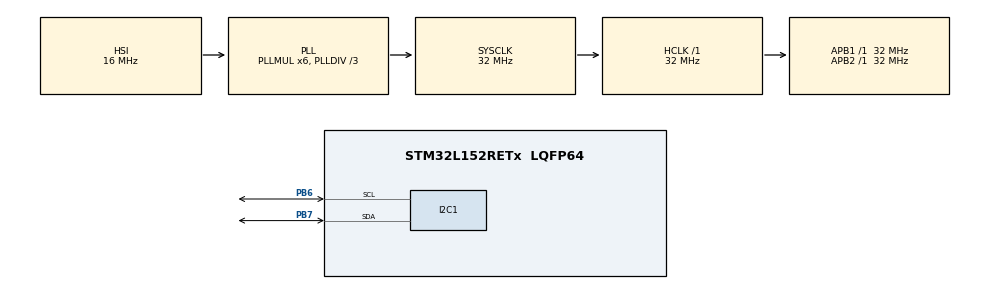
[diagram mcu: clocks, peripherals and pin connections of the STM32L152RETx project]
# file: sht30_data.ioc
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Mcu.Family=STM32L1
Mcu.Name=STM32L152RETx
Mcu.Package=LQFP64
NVIC.PriorityGroup=NVIC_PRIORITYGROUP_0
PA13.Mode=Trace_Asynchronous_SW
PA13.Signal=SYS_JTMS-SWDIO
PA14.Mode=Trace_Asynchronous_SW
PA14.Signal=SYS_JTCK-SWCLK
PB3.Mode=Trace_Asynchronous_SW
PB3.Signal=SYS_JTDO-TRACESWO
PB6.GPIO_Pu=GPIO_PULLUP
PB6.Mode=I2C
PB6.Signal=I2C1_SCL
PB7.GPIO_Pu=GPIO_PULLUP
PB7.Mode=I2C
PB7.Signal=I2C1_SDA
ProjectManager.HeapSize=0x200
ProjectManager.StackSize=0x400
ProjectManager.TargetToolchain=STM32CubeIDE
RCC.48MHZClocksFreq_Value=48000000
RCC.AHBFreq_Value=32000000
RCC.APB1Freq_Value=32000000
RCC.APB1TimFreq_Value=32000000
RCC.APB2Freq_Value=32000000
RCC.APB2TimFreq_Value=32000000
RCC.HCLKFreq_Value=32000000
RCC.HSE_VALUE=8000000
RCC.HSI_VALUE=16000000
RCC.LSE_VALUE=32768
RCC.MSI_VALUE=2097000
RCC.PLLDIV=RCC_PLL_DIV3
RCC.PLLMUL=RCC_PLL_MUL6
RCC.RTCClockSelectionVirtual=RCC_RTCCLKSOURCE_LSE
RCC.SYSCLKFreq_VALUE=32000000
RCC.SYSCLKSource=RCC_SYSCLKSOURCE_PLLCLK
RCC.USBOutput=48000000
RCC.VCOOutputFreq_Value=96000000
board=NUCLEO-L152RE

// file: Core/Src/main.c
/* USER CODE BEGIN Header */
/**
  ******************************************************************************
  * @file           : main.c
  * @brief          : Main program body
  ******************************************************************************
  * @attention
  *
  * Copyright (c) 2024 STMicroelectronics.
  * All rights reserved.
  *
  * This software is licensed under terms that can be found in the LICENSE file
  * in the root directory of this software component.
  * If no LICENSE file comes with this software, it is provided AS-IS.
  *
  ******************************************************************************
  */
/* USER CODE END Header */
#include "main.h"

/* USER CODE BEGIN Includes */
#include <string.h>
#include <stdio.h>

/* USER CODE END Includes */

I2C_HandleTypeDef hi2c1;

/* USER CODE BEGIN PV */
#define SHT30_SENSOR_ADDR           (0x44   << 1)  // SHT30 sensor address
#define SHT30_MEAS_HIGHREP_STRETCH  0x2C06  // Measurement command for high repeatability with clock stretching

float temperature;
float humidity;
uint16_t temperature_raw, humidity_raw;

/* USER CODE END PV */

void SystemClock_Config(void);
static void MX_GPIO_Init(void);
static void MX_I2C1_Init(void);

/* USER CODE BEGIN 0 */
HAL_StatusTypeDef SHT30_ReadTempHum()
{
	uint8_t cmd[2] = {(SHT30_MEAS_HIGHREP_STRETCH >> 8), (SHT30_MEAS_HIGHREP_STRETCH & 0xFF)};
	uint8_t data[6];

	if(HAL_I2C_Master_Transmit(&hi2c1, SHT30_SENSOR_ADDR, cmd, 2, HAL_MAX_DELAY) != HAL_OK)
		return HAL_ERROR;

	HAL_Delay(15);

	if(HAL_I2C_Master_Receive(&hi2c1, SHT30_SENSOR_ADDR, data, 6, HAL_MAX_DELAY) != HAL_OK)
		return HAL_ERROR;
	uint16_t temperature_raw = (data[0] << 8)| data[1];
	uint16_t humidity_raw = (data[3] << 8) | data[4];

	temperature = -45.0f + 175.0f * temperature_raw / 65535.0f;;
	humidity = 100.0f * humidity_raw / 65535.0f;

	return HAL_OK;
}

/* USER CODE END 0 */

int main(void)
{

  /* MCU Configuration--------------------------------------------------------*/

  /* Reset of all peripherals, Initializes the Flash interface and the Systick. */
  HAL_Init();

  /* Configure the system clock */
  SystemClock_Config();

  /* Initialize all configured peripherals */
  MX_GPIO_Init();
  MX_I2C1_Init();

  /* Infinite loop */
  /* USER CODE BEGIN WHILE */
  while (1)
  {
	  if(SHT30_ReadTempHum() == HAL_OK)
	  {
		  printf("Temperature = %.2f | Humidity = %.2f", temperature, humidity);
		  HAL_Delay(2000);
	  }
	  else
	  {
		  printf("Error Timed Out");
	  }
    /* USER CODE END WHILE */

  }
}

void SystemClock_Config(void)
{
  RCC_OscInitTypeDef RCC_OscInitStruct = {0};
  RCC_ClkInitTypeDef RCC_ClkInitStruct = {0};

  /** Configure the main internal regulator output voltage
  */
  __HAL_PWR_VOLTAGESCALING_CONFIG(PWR_REGULATOR_VOLTAGE_SCALE1);

  /** Initializes the RCC Oscillators according to the specified parameters
  * in the RCC_OscInitTypeDef structure.
  */
  RCC_OscInitStruct.OscillatorType = RCC_OSCILLATORTYPE_HSI;
  RCC_OscInitStruct.HSIState = RCC_HSI_ON;
  RCC_OscInitStruct.HSICalibrationValue = RCC_HSICALIBRATION_DEFAULT;
  RCC_OscInitStruct.PLL.PLLState = RCC_PLL_ON;
  RCC_OscInitStruct.PLL.PLLSource = RCC_PLLSOURCE_HSI;
  RCC_OscInitStruct.PLL.PLLMUL = RCC_PLL_MUL6;
  RCC_OscInitStruct.PLL.PLLDIV = RCC_PLL_DIV3;
  if (HAL_RCC_OscConfig(&RCC_OscInitStruct) != HAL_OK)
  {
    Error_Handler();
  }

  /** Initializes the CPU, AHB and APB buses clocks
  */
  RCC_ClkInitStruct.ClockType = RCC_CLOCKTYPE_HCLK|RCC_CLOCKTYPE_SYSCLK
                              |RCC_CLOCKTYPE_PCLK1|RCC_CLOCKTYPE_PCLK2;
  RCC_ClkInitStruct.SYSCLKSource = RCC_SYSCLKSOURCE_PLLCLK;
  RCC_ClkInitStruct.AHBCLKDivider = RCC_SYSCLK_DIV1;
  RCC_ClkInitStruct.APB1CLKDivider = RCC_HCLK_DIV1;
  RCC_ClkInitStruct.APB2CLKDivider = RCC_HCLK_DIV1;

  if (HAL_RCC_ClockConfig(&RCC_ClkInitStruct, FLASH_LATENCY_1) != HAL_OK)
  {
    Error_Handler();
  }
}

static void MX_I2C1_Init(void)
{

  hi2c1.Instance = I2C1;
  hi2c1.Init.ClockSpeed = 100000;
  hi2c1.Init.DutyCycle = I2C_DUTYCYCLE_2;
  hi2c1.Init.OwnAddress1 = 0;
  hi2c1.Init.AddressingMode = I2C_ADDRESSINGMODE_7BIT;
  hi2c1.Init.DualAddressMode = I2C_DUALADDRESS_DISABLE;
  hi2c1.Init.OwnAddress2 = 0;
  hi2c1.Init.GeneralCallMode = I2C_GENERALCALL_DISABLE;
  hi2c1.Init.NoStretchMode = I2C_NOSTRETCH_DISABLE;
  if (HAL_I2C_Init(&hi2c1) != HAL_OK)
  {
    Error_Handler();
  }

}

static void MX_GPIO_Init(void)
{

  /* GPIO Ports Clock Enable */
  __HAL_RCC_GPIOA_CLK_ENABLE();
  __HAL_RCC_GPIOB_CLK_ENABLE();

}

void Error_Handler(void)
{
  __disable_irq();
  while (1)
  {
  }
}
